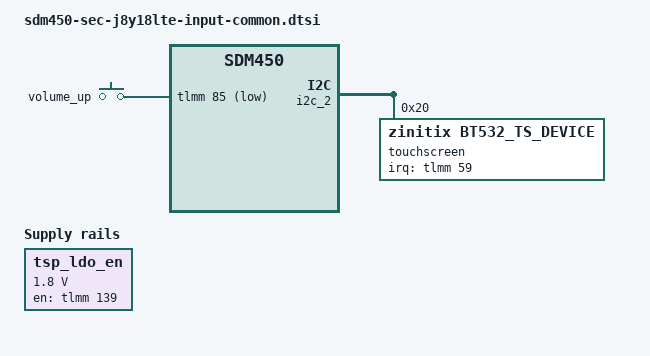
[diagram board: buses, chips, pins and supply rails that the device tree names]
/* Copyright (c) 2017, The Linux Foundation. All rights reserved.
 *
 * This program is free software; you can redistribute it and/or modify
 * it under the terms of the GNU General Public License version 2 and
 * only version 2 as published by the Free Software Foundation.
 *
 * This program is distributed in the hope that it will be useful,
 * but WITHOUT ANY WARRANTY; without even the implied warranty of
 * MERCHANTABILITY or FITNESS FOR A PARTICULAR PURPOSE.  See the
 * GNU General Public License for more details.
 */

#include <dt-bindings/input/input.h>

/ {
	tsp_ldo_en {
		compatible = "regulator-fixed";
		regulator-name = "tsp_ldo_en";
		regulator-min-microvolt = <1800000>;
		regulator-max-microvolt = <1800000>;
		gpio = <&tlmm 139 0>;
		enable-active-high;
		regulator-boot-on;
	};

	sec-debug {
		tsp_dump {
			keys = <KEY_VOLUMEUP KEY_VOLUMEDOWN KEY_VOLUMEDOWN>;
		};
	};
};

&soc {
	gpio_keys {
		compatible = "gpio-keys";
		input-name = "gpio-keys";
		pinctrl-names = "tlmm_gpio_key_active","tlmm_gpio_key_suspend";
		pinctrl-0 = <&gpio_key_active>;
		pinctrl-1 = <&gpio_key_suspend>;

		vol_up {
			label = "volume_up";
			gpios = <&tlmm 85 0x1>;
			linux,input-type = <1>;
			linux,code = <KEY_VOLUMEUP>;
			debounce-interval = <15>;
		};
	};

	i2c_2: i2c@78b6000 {
		status = "okay";
		touchscreen@20 {
			compatible = "zinitix,bt532_ts_device";
			reg = <0x20>;
			pinctrl-names = "on_state", "off_state";
			pinctrl-0 = <&tsp_int_active>;
			pinctrl-1 = <&tsp_int_suspend>;
			zinitix,irq_gpio = <&tlmm 59 0>;
			zinitix,gpio_ldo_en;
			zinitix,regulator_avdd = "tsp_ldo_en";
			zinitix,x_resolution = <720>;
			zinitix,y_resolution = <1480>;
			zinitix,area-size = <48 96 60>; /* indicator: 24dp navigator:48dp edge:60px dpi=320*/
			zinitix,page_size = <128>;
			zinitix,chip_name = "ZT7548";
			zinitix,firmware_name = "tsp_zinitix/zt7548_j8.fw";
			zinitix,spay;
			/* zinitix,aod */
			zinitix,tclm_level = <0x02>;
			zinitix,afe_base = <0x8009>;
			zinitix,mis_cal_check;
			zinitix,factory_item_version = <4>;
			status = "okay";
		};
	};
};
